# PIC32MM0064GPL020 register map
Vendor: Microchip
Registers are 32-bit, read-write, reset 0x0 unless marked. A register's access mark holds for its fields unless they carry their own. Addresses are absolute, and some are shared; only a register's first bit layout is shown; [hi:lo] are bit positions; {n}, {i} and the like mark numbered series.

## cmp_control_upb
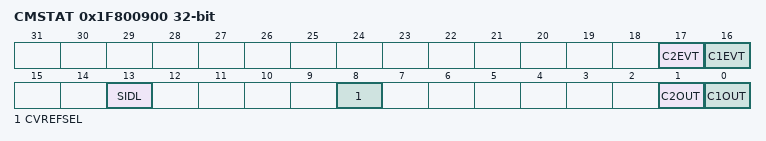
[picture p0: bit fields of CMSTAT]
0x1F800900 CMSTAT
  [17] C2EVT ro, [16] C1EVT ro, [13] SIDL, [8] CVREFSEL, [1] C2OUT ro, [0] C1OUT ro

## CMP1
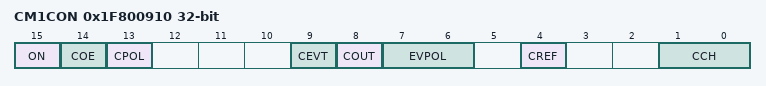
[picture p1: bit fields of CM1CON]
0x1F800910 CM1CON
  [15] ON, [14] COE, [13] CPOL, [9] CEVT, [8] COUT ro, [7:6] EVPOL, [4] CREF, [1:0] CCH

## CMP2
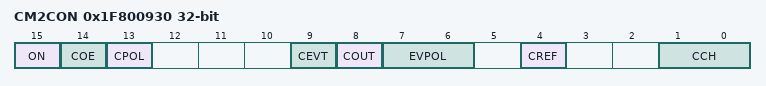
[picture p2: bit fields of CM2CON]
0x1F800930 CM2CON
  [15] ON, [14] COE, [13] CPOL, [9] CEVT, [8] COUT ro, [7:6] EVPOL, [4] CREF, [1:0] CCH

## CDAC1
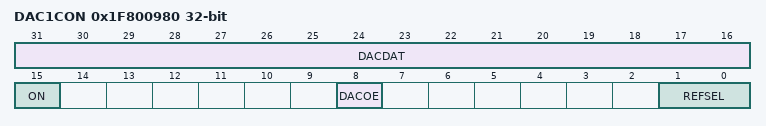
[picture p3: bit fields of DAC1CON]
0x1F800980 DAC1CON — CDAC Control Register
  [31:16] DACDAT — Data Input Register Bits for the CDAC
  [15] ON — CDAC Enable
    0=The CDAC is Disabled; 1=The CDAC is Enabled
  [8] DACOE — CDAC Output Enable
    0=Output is Disabled; drive to pin is floating; 1=Output is Enabled; CDAC voltage is connected to the pin
  [1:0] REFSEL — Reference Source Select
    0=No Reference Selected (no current consumed); 1=Positive Reference Voltage = External Vref+ Pin; 2=Positive Reference Voltage = 2 * Internal Bandgap Reference Voltage; 3=Positive Reference Voltage = AVdd

## CRC
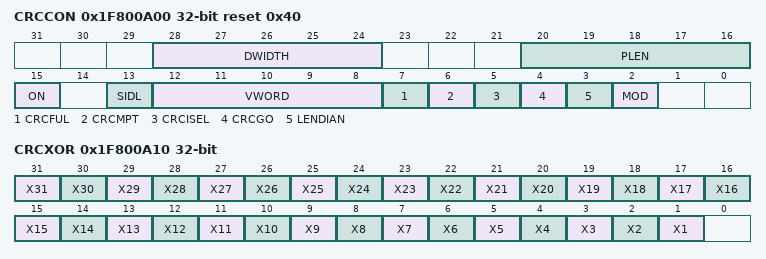
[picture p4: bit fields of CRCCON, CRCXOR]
0x1F800A00 CRCCON reset 0x40
  [28:24] DWIDTH, [20:16] PLEN, [15] ON, [13] SIDL, [12:8] VWORD ro, [7] CRCFUL ro, [6] CRCMPT ro, [5] CRCISEL, [4] CRCGO, [3] LENDIAN, [2] MOD
0x1F800A10 CRCXOR
  [n] X{n} (n=1..31)
0x1F800A20 CRCDAT wo
0x1F800A30 CRCWDAT

## CLC1
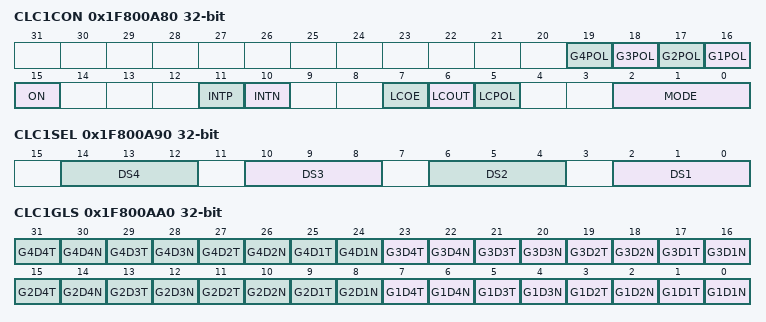
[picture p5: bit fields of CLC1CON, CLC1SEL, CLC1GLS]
0x1F800A80 CLC1CON
  [n+15] G{n}POL (n=1..4), [15] ON, [11] INTP, [10] INTN, [7] LCOE, [6] LCOUT, [5] LCPOL, [2:0] MODE
0x1F800A90 CLC1SEL
  [4n-2:4n-4] DS{n} (n=1..4)
0x1F800AA0 CLC1GLS
  [8n-1] G{n}D4T (n=1..4), [8n-2] G{n}D4N (n=1..4), [8n-3] G{n}D3T (n=1..4), [8n-4] G{n}D3N (n=1..4), [8n-5] G{n}D2T (n=1..4), [8n-6] G{n}D2N (n=1..4), [8n-7] G{n}D1T (n=1..4), [8n-8] G{n}D1N (n=1..4)

## CLC2
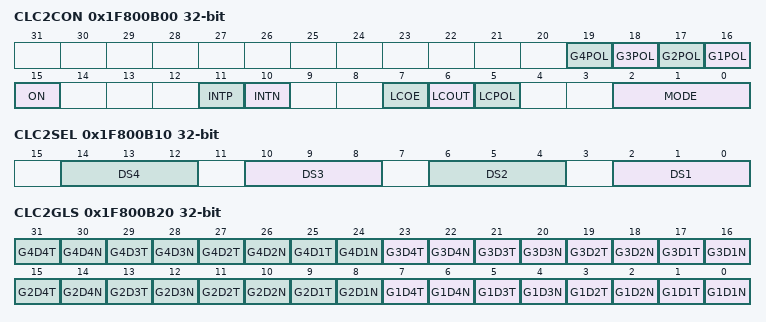
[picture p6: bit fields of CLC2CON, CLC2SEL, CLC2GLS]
0x1F800B00 CLC2CON
  [n+15] G{n}POL (n=1..4), [15] ON, [11] INTP, [10] INTN, [7] LCOE, [6] LCOUT, [5] LCPOL, [2:0] MODE
0x1F800B10 CLC2SEL
  [4n-2:4n-4] DS{n} (n=1..4)
0x1F800B20 CLC2GLS
  [8n-1] G{n}D4T (n=1..4), [8n-2] G{n}D4N (n=1..4), [8n-3] G{n}D3T (n=1..4), [8n-4] G{n}D3N (n=1..4), [8n-5] G{n}D2T (n=1..4), [8n-6] G{n}D2N (n=1..4), [8n-7] G{n}D1T (n=1..4), [8n-8] G{n}D1N (n=1..4)

## CRU
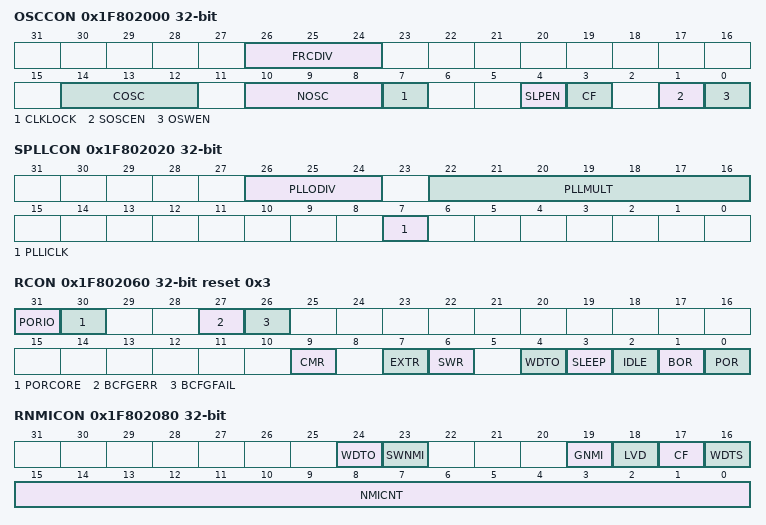
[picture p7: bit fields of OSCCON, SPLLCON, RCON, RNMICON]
0x1F802000 OSCCON reset not defined — (power-on value -----000---------000-xxx0--00-x0)
  [26:24] FRCDIV, [14:12] COSC ro, [10:8] NOSC, [7] CLKLOCK, [4] SLPEN, [3] CF, [1] SOSCEN, [0] OSWEN
0x1F802020 SPLLCON reset not defined — (power-on value -----001-xxxxxxx--------0-------)
  [26:24] PLLODIV, [22:16] PLLMULT, [7] PLLICLK
0x1F802060 RCON reset 0x3
  [31] PORIO, [30] PORCORE, [27] BCFGERR, [26] BCFGFAIL, [9] CMR, [7] EXTR, [6] SWR, [4] WDTO, [3] SLEEP, [2] IDLE, [1] BOR, [0] POR
0x1F802070 RSWRST wo
  [0] SWRST
0x1F802080 RNMICON reset not defined — (power-on value -------x0---0-000000000000000000)
  [24] WDTO, [23] SWNMI, [19] GNMI, [18] LVD, [17] CF, [16] WDTS, [15:0] NMICNT
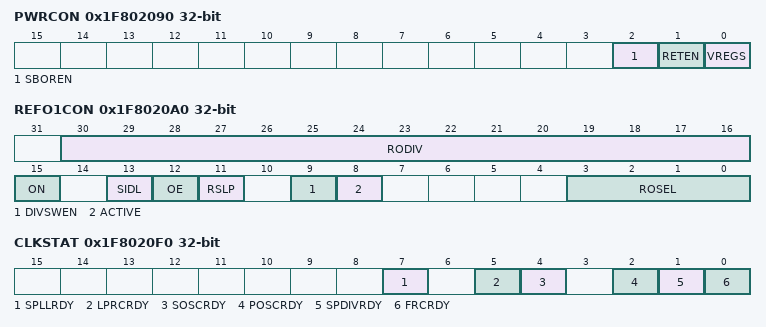
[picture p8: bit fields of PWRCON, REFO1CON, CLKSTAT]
0x1F802090 PWRCON
  [2] SBOREN, [1] RETEN, [0] VREGS
0x1F8020A0 REFO1CON
  [30:16] RODIV, [15] ON, [13] SIDL, [12] OE, [11] RSLP, [9] DIVSWEN, [8] ACTIVE ro, [3:0] ROSEL
0x1F8020B0 REFO1TRIM
  [31:23] ROTRIM
0x1F8020F0 CLKSTAT reset not defined — (power-on value ------------------------0-00-0x0)
  [7] SPLLRDY ro, [5] LPRCRDY ro, [4] SOSCRDY ro, [2] POSCRDY ro, [1] SPDIVRDY, [0] FRCRDY ro

## FRC
0x1F802200 OSCTUN
  [5:0] TUN

## SABA
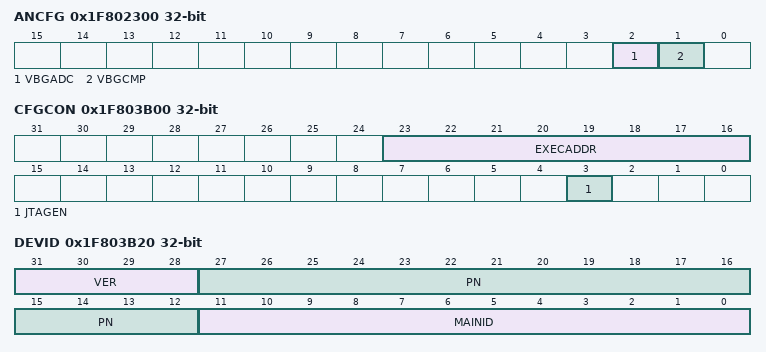
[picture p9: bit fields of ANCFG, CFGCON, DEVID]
0x1F802300 ANCFG
  [2] VBGADC, [1] VBGCMP
0x1F803B00 CFGCON
  [23:16] EXECADDR, [3] JTAGEN
0x1F803B20 DEVID ro reset not defined — (power-on value xxxxxxxxxxxxxxxxxxxxxxxxxxxxxxxx)
  [31:28] VER, [27:12] PN, [11:0] MAINID
0x1F803B30 SYSKEY wo
